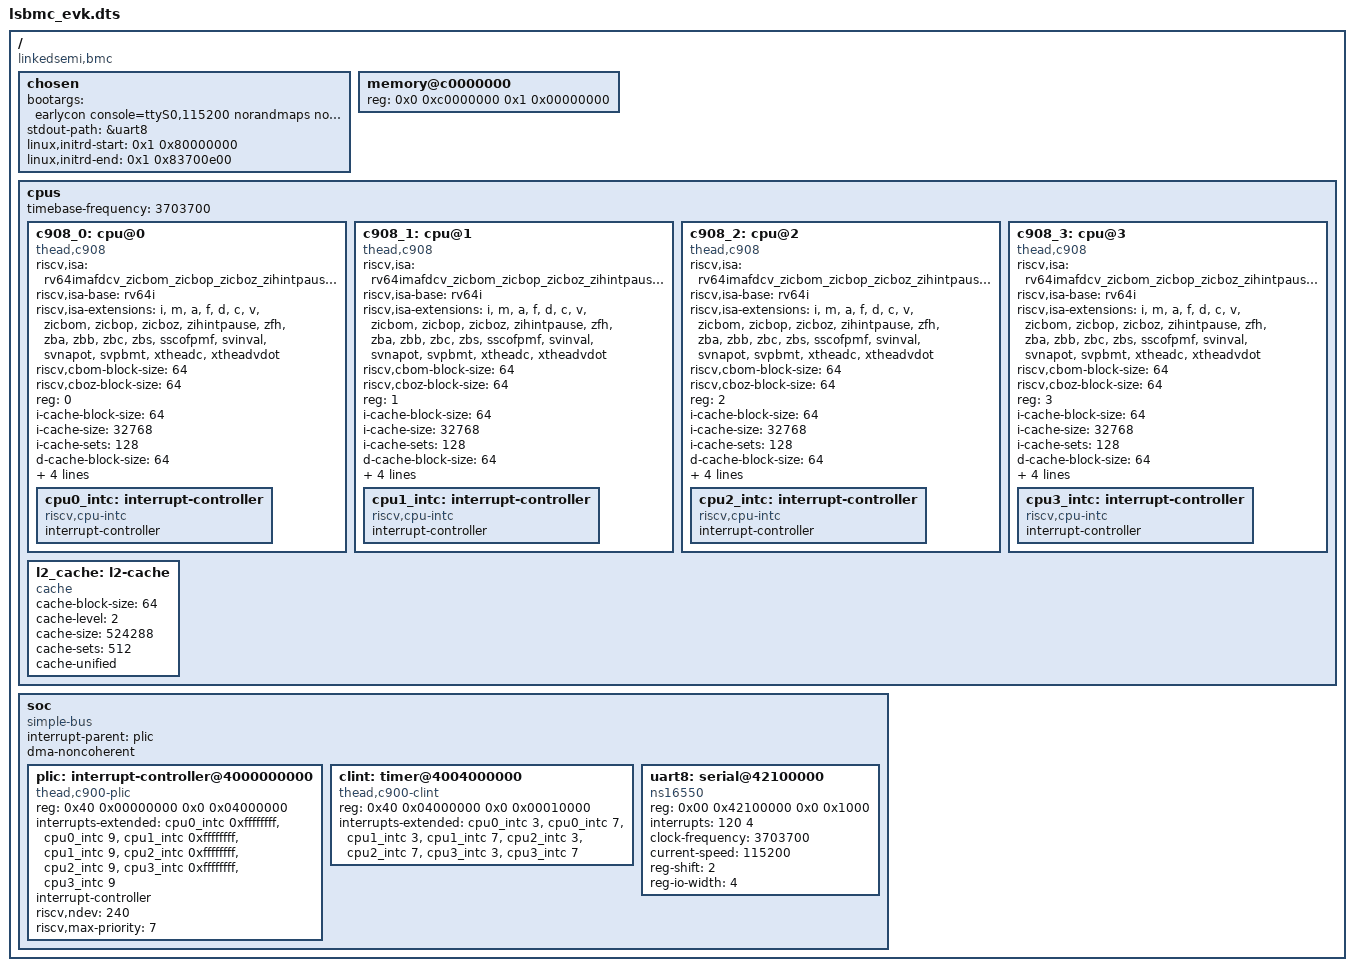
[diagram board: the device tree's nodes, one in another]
/dts-v1/;

/ {
    compatible = "linkedsemi,bmc";
    #address-cells = <2>;
	#size-cells = <2>;
	chosen {
		bootargs = "earlycon console=ttyS0,115200 norandmaps no_check_unaligned_access no4lvl debug";
		stdout-path = &uart8;
		linux,initrd-start = <0x1 0x80000000>; 
		linux,initrd-end = <0x1 0x83700e00>; 
	};

    memory@c0000000 {
		device_type = "memory";
		reg = <0x0 0xc0000000 0x1 0x00000000>;
	};

	cpus: cpus {
		#address-cells = <1>;
		#size-cells = <0>;
		timebase-frequency = <3703700>;

		c908_0: cpu@0 {
			compatible = "thead,c908", "riscv";
			device_type = "cpu";
			riscv,isa = "rv64imafdcv_zicbom_zicbop_zicboz_zihintpause_zfh_zba_zbb_zbc_zbs_sscofpmf_svinval_svnapot_svpbmt_xtheadc_xtheadvdot";
			riscv,isa-base = "rv64i";
			riscv,isa-extensions = "i","m","a","f","d","c","v","zicbom","zicbop","zicboz","zihintpause",
				"zfh","zba","zbb","zbc","zbs","sscofpmf","svinval","svnapot","svpbmt","xtheadc","xtheadvdot";
			riscv,cbom-block-size = <64>;
			riscv,cboz-block-size = <64>;
			reg = <0>;
			i-cache-block-size = <64>;
			i-cache-size = <32768>;
			i-cache-sets = <128>;
			d-cache-block-size = <64>;
			d-cache-size = <32768>;
			d-cache-sets = <128>;
			next-level-cache = <&l2_cache>;
			mmu-type = "riscv,sv39";

			cpu0_intc: interrupt-controller {
				compatible = "riscv,cpu-intc";
				interrupt-controller;
				#interrupt-cells = <1>;
                #address-cells = <0>;
			};
		};

		c908_1: cpu@1 {
			compatible = "thead,c908", "riscv";
			device_type = "cpu";
			riscv,isa = "rv64imafdcv_zicbom_zicbop_zicboz_zihintpause_zfh_zba_zbb_zbc_zbs_sscofpmf_svinval_svnapot_svpbmt_xtheadc_xtheadvdot";
			riscv,isa-base = "rv64i";
			riscv,isa-extensions = "i","m","a","f","d","c","v","zicbom","zicbop","zicboz","zihintpause",
				"zfh","zba","zbb","zbc","zbs","sscofpmf","svinval","svnapot","svpbmt","xtheadc","xtheadvdot";
			riscv,cbom-block-size = <64>;
			riscv,cboz-block-size = <64>;
			reg = <1>;
			i-cache-block-size = <64>;
			i-cache-size = <32768>;
			i-cache-sets = <128>;
			d-cache-block-size = <64>;
			d-cache-size = <32768>;
			d-cache-sets = <128>;
			next-level-cache = <&l2_cache>;
			mmu-type = "riscv,sv39";

			cpu1_intc: interrupt-controller {
				compatible = "riscv,cpu-intc";
				interrupt-controller;
				#interrupt-cells = <1>;
                #address-cells = <0>;
			};
		};

		c908_2: cpu@2 {
			compatible = "thead,c908", "riscv";
			device_type = "cpu";
			riscv,isa = "rv64imafdcv_zicbom_zicbop_zicboz_zihintpause_zfh_zba_zbb_zbc_zbs_sscofpmf_svinval_svnapot_svpbmt_xtheadc_xtheadvdot";
			riscv,isa-base = "rv64i";
			riscv,isa-extensions = "i","m","a","f","d","c","v","zicbom","zicbop","zicboz","zihintpause",
				"zfh","zba","zbb","zbc","zbs","sscofpmf","svinval","svnapot","svpbmt","xtheadc","xtheadvdot";
			riscv,cbom-block-size = <64>;
			riscv,cboz-block-size = <64>;
			reg = <2>;
			i-cache-block-size = <64>;
			i-cache-size = <32768>;
			i-cache-sets = <128>;
			d-cache-block-size = <64>;
			d-cache-size = <32768>;
			d-cache-sets = <128>;
			next-level-cache = <&l2_cache>;
			mmu-type = "riscv,sv39";

			cpu2_intc: interrupt-controller {
				compatible = "riscv,cpu-intc";
				interrupt-controller;
				#interrupt-cells = <1>;
                #address-cells = <0>;
			};
		};

		c908_3: cpu@3 {
			compatible = "thead,c908", "riscv";
			device_type = "cpu";
			riscv,isa = "rv64imafdcv_zicbom_zicbop_zicboz_zihintpause_zfh_zba_zbb_zbc_zbs_sscofpmf_svinval_svnapot_svpbmt_xtheadc_xtheadvdot";
			riscv,isa-base = "rv64i";
			riscv,isa-extensions = "i","m","a","f","d","c","v","zicbom","zicbop","zicboz","zihintpause",
				"zfh","zba","zbb","zbc","zbs","sscofpmf","svinval","svnapot","svpbmt","xtheadc","xtheadvdot";
			riscv,cbom-block-size = <64>;
			riscv,cboz-block-size = <64>;
			reg = <3>;
			i-cache-block-size = <64>;
			i-cache-size = <32768>;
			i-cache-sets = <128>;
			d-cache-block-size = <64>;
			d-cache-size = <32768>;
			d-cache-sets = <128>;
			next-level-cache = <&l2_cache>;
			mmu-type = "riscv,sv39";

			cpu3_intc: interrupt-controller {
				compatible = "riscv,cpu-intc";
				interrupt-controller;
				#interrupt-cells = <1>;
                #address-cells = <0>;
			};
		};
		l2_cache: l2-cache {
			compatible = "cache";
			cache-block-size = <64>;
			cache-level = <2>;
			cache-size = <524288>;
			cache-sets = <512>;
			cache-unified;
		};
    };

	soc {
		compatible = "simple-bus";
		interrupt-parent = <&plic>;
		#address-cells = <2>;
		#size-cells = <2>;
		dma-noncoherent;
		ranges;

		plic: interrupt-controller@4000000000 {
			compatible =  "thead,c900-plic";
			reg = <0x40 0x00000000 0x0 0x04000000>;
			interrupts-extended = <&cpu0_intc 0xffffffff>, <&cpu0_intc 9>,
					      <&cpu1_intc 0xffffffff>, <&cpu1_intc 9>,
					      <&cpu2_intc 0xffffffff>, <&cpu2_intc 9>,
					      <&cpu3_intc 0xffffffff>, <&cpu3_intc 9>;
			interrupt-controller;
			#address-cells = <0>;
			#interrupt-cells = <2>;
			riscv,ndev = <240>;
            riscv,max-priority = <7>;
		};

		clint: timer@4004000000 {
			compatible = "thead,c900-clint";
			reg = <0x40 0x04000000 0x0 0x00010000>;
			interrupts-extended = <&cpu0_intc 3>, <&cpu0_intc 7>,
					      <&cpu1_intc 3>, <&cpu1_intc 7>,
					      <&cpu2_intc 3>, <&cpu2_intc 7>,
					      <&cpu3_intc 3>, <&cpu3_intc 7>;
		};

		uart8: serial@42100000 {
			compatible = "ns16550";
			reg = <0x00 0x42100000 0x0 0x1000>;
			interrupts = <120 4>;
            clock-frequency = <3703700>;
			current-speed = <115200>;
			reg-shift = <2>;
			reg-io-width = <4>;
			status = "okay";
		};
    };
};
